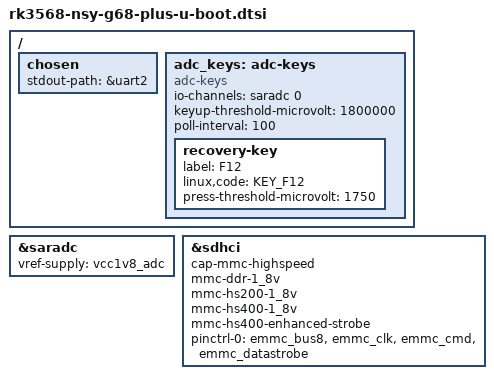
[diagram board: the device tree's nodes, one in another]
// SPDX-License-Identifier: GPL-2.0-or-later OR MIT

#include "rk356x-u-boot.dtsi"

/ {
	chosen {
		stdout-path = &uart2;
	};

	adc_keys: adc-keys {
		compatible = "adc-keys";
		io-channels = <&saradc 0>;
		io-channel-names = "buttons";
		keyup-threshold-microvolt = <1800000>;
		poll-interval = <100>;
		status = "okay";
		recovery-key {
			label = "F12";
			linux,code = <KEY_F12>;
			press-threshold-microvolt = <1750>;
		};
	};
};

&saradc {
	status = "okay";
	vref-supply = <&vcc1v8_adc>;
};

&sdhci {
	cap-mmc-highspeed;
	mmc-ddr-1_8v;
	mmc-hs200-1_8v;
	mmc-hs400-1_8v;
	mmc-hs400-enhanced-strobe;
	pinctrl-0 = <&emmc_bus8 &emmc_clk &emmc_cmd &emmc_datastrobe>;
};
